# R40 register map
Vendor: Allwinner; Series: R40; File version: 0.1
CPU: CA7 0, little endian, MPU, FPU, double-precision FPU, 0 interrupt priority bits
Registers are 32-bit, read-write, reset 0x0 unless marked. A register's access mark holds for its fields unless they carry their own. Offsets are from the block's base; [hi:lo] are bit positions; {n}, {i} and the like mark numbered series; 'fields as' and 'values as' point back to an identical list.

## TVE0
Base 0x01C94000
Same registers: TVE1 0x01C98000
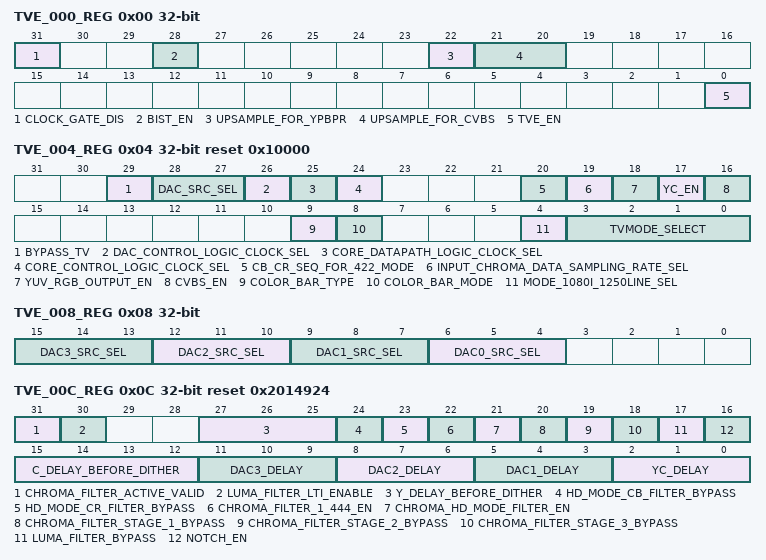
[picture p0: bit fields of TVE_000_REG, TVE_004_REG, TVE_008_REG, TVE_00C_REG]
0x00 TVE_000_REG — TV Encoder Clock Gating Register
  [31] CLOCK_GATE_DIS — CLOCK_GATE_DIS 0: Enable 1: Disable
    0=Enable; 1=Disable
  [28] BIST_EN — BIST_EN 0: Normal mode 1: Bist mode
    0=Normal_mode; 1=Bist_mode
  [22] UPSAMPLE_FOR_YPBPR — upsample for YPbPr 0:1x 1:2x
  [21:20] UPSAMPLE_FOR_CVBS — upsample for CVBS Out up sample 00: 27MHz 01: 54MHz 10: 108MHz 11: 216MHz
    0=_27MHz; 1=_54MHz; 2=_108MHz; 3=_216MHz
  [0] TVE_EN — TVE_EN 0: Disable 1: Enable Note: Video Encoder enable, default disable, write 1 to take it out of the reset state
    0=Disable; 1=Enable Note: Video Encoder enable, default disable, write 1 to take it out of the reset state
0x04 TVE_004_REG reset 0x10000 — TV Encoder Configuration Register
  [29] BYPASS_TV — 0: Disable 1: Enable
    0=Disable; 1=Enable
  [28:27] DAC_SRC_SEL — 00: TV Encoder 01: LCD controller, override all other TV encoder setting, the DAC clock can from LCD controller. 10: DAC test mode,DAC using DAC clock 11: DAC test mode, DAC using AHB clock
  [26] DAC_CONTROL_LOGIC_CLOCK_SEL — 0: Using 27MHz clock or 74.25MHz clock depend on CCU setting 1: Using 54MHz clock or 148.5MHz clock depend on CCU setting
    0=_27MHz (Using 27MHz clock or 74.25MHz clock depend on CCU setting); 1=_54MHz (Using 54MHz clock or 148.5MHz clock depend on CCU setting)
  [25] CORE_DATAPATH_LOGIC_CLOCK_SEL — 0: Using 27MHz clock or 74.25MHz clock depend on CCU setting 1: Using 54MHz clock or 148.5MHz clock depend on CCU setting
    values as DAC_CONTROL_LOGIC_CLOCK_SEL
  [24] CORE_CONTROL_LOGIC_CLOCK_SEL — 0: Using 27MHz clock or 74.25MHz clock depend on CCU setting 1: Using 54MHz clock or 148.5MHz clock depend on CCU setting
    values as DAC_CONTROL_LOGIC_CLOCK_SEL
  [20] CB_CR_SEQ_FOR_422_MODE — 0: Cb first 1: Cr first
    0=Cb (Cb first); 1=Cr (Cr first)
  [19] INPUT_CHROMA_DATA_SAMPLING_RATE_SEL — 0: 4:4:4 1: 4:2:2
    0=_4_colon_4_colon_4 (4:4:4); 1=_4_colon_2_colon_2 (4:2:2)
  [18] YUV_RGB_OUTPUT_EN — 0: CVBS or/and Y/C 1: YUV (or RGB) Note: Only apply to SD interlace mode, when in progressive mode, output YPbPr (RGB) only
    0=CVBS (CVBS or/and Y/C); 1=YUV (YUV (or RGB) Note: Only apply to SD interlace mode, when in progressive mode, output YPbPr (RGB) only)
  [17] YC_EN — 0: Y/C is disable 1: Y/C enable Note: S-port Video enable Selection. This bit selects whether the S-port(Y/C) video output is enabled or disabled.
    0=Y_slash_C (Y/C is disable); 1=Y_slash_C_enable (Y/C enable Note: S-port Video enable Selection. This bit selects whether the S-port(Y/C) video output is enabled or disabled.)
  [16] CVBS_EN — 0: Composite video is disabled, Only Y/C is enable 1: Composite video is enabled., CVBS and Y/C enable Note: Composite Video enable Selection This bit selects whether the composite video output (CVBS) is enabled or disabled.
    0=disabled (Composite video is disabled, Only Y/C is enable); 1=enabled (Composite video is enabled., CVBS and Y/C enable Note: Composite Video enable Selection This bit selects whether the composite video output (CVBS) is enabled or disabled.)
  [9] COLOR_BAR_TYPE — 0: 75/7.5/75/7.5 (NTSC), 100/0/75/0(PAL) 1: 100/7.5/100/7.5(NTSC), 100/0/100/0(PAL)
    0=_75_slash_7_point_5_slash_75_slash_7_point_5 (75/7.5/75/7.5 (NTSC), 100/0/75/0(PAL)); 1=_100_slash_7_point_5_slash_100_slash_7_point_5_openingparen_NTSC_closingparen_ (100/7.5/100/7.5(NTSC), 100/0/100/0(PAL))
  [8] COLOR_BAR_MODE — 0: The Video Encoder input is coming from the Display Engineer 1: The Video Encoder input is coming from an internal standard color bar generator. Note: Standard Color bar input selection This bit selects whether the Video Encoder video data input is replaced by an internal standard color bar generator or not.
    0=coming_from_the_Display (The Video Encoder input is coming from the Display Engineer); 1=coming_from_an (The Video Encoder input is coming from an internal standard color bar generator. Note: Standard Color bar input selection This bit selects whether the Video Encoder video data input is replaced by an internal standard color bar generator or not.)
  [4] MODE_1080I_1250LINE_SEL — 0: 1125 Line mode 1: 1250 Line mode
    0=1125 Line mode; 1=1250 Line mode
  [3:0] TVMODE_SELECT — 0000: 480i 0001: 576i 0010: 480p 0011: 576p 01xx: Reserved 100x: Reserved 101x: 720p 110x: 1080i 111x: 1080p Note: Changing this register value will cause some relative register setting to relative value.
    0=_480i; 1=_576i; 2=_480p; 3=_576p; 10=_720p; 12=_1080i; 14=1080p Note: Changing this register value will cause some relative register setting to relative value
0x08 TVE_008_REG — TV Encoder DAC Register1
  [all] fields
    0=Composite; 1=Luma; 2=Chroma; 4=Y_slash_Green (Y/Green); 5=U_slash_Pb_slash_Blue (U/Pb/Blue); 6=V_slash_Pr_slash_Red (V/Pr/Red)
  [3n+6:3n+4] DAC{n}_SRC_SEL (n=0..3) — 000: Composite 001: Luma 010: Chroma 011: Reserved 100: Y/Green 101: U/Pb/Blue 110: V/Pr/Red 111: Reserved
0x0C TVE_00C_REG reset 0x2014924 — TV Encoder Notch and DAC Delay Register
  [31] CHROMA_FILTER_ACTIVE_VALID — 0: Disable 1: Enable
    0=Disable; 1=Enable
  [30] LUMA_FILTER_LTI_ENABLE — 0: Disable Luma filter lti 1: Enable Luma filter lti
    0=Disable Luma filter lti; 1=Enable Luma filter lti
  [27:25] Y_DELAY_BEFORE_DITHER
  [24] HD_MODE_CB_FILTER_BYPASS — 0: Bypass Enable 1: Bypass Disable
    0=Bypass_Enable; 1=Bypass_Disable
  [23] HD_MODE_CR_FILTER_BYPASS — 0: Bypass Enable 1: Bypass Disable
    0=Bypass_Enable; 1=Bypass_Disable
  [22] CHROMA_FILTER_1_444_EN — 0: Chroma Filter 1 444 Disable 1: Chroma Filter 1 444 Enable
    0=Chroma_Filter_1_444_Disable; 1=Chroma_Filter_1_444_Enable
  [21] CHROMA_HD_MODE_FILTER_EN — 0: Chroma HD Filter Disable 1: Chroma HD Filter Enable
    0=Chroma_HD_Filter_Disable; 1=Chroma_HD_Filter_Enable
  [20] CHROMA_FILTER_STAGE_1_BYPASS — 0: Chroma Filter Stage 1 Enable 1: Chroma Filter Stage 1 bypass
    0=Chroma_Filter_Stage_1_Enable; 1=Chroma_Filter_Stage_1_bypass
  [19] CHROMA_FILTER_STAGE_2_BYPASS — 0: Chroma Filter Stage 2 Enable 1: Chroma Filter Stage 2 bypass
    0=Chroma_Filter_Stage_2_Enable; 1=Chroma_Filter_Stage_2_bypass
  [18] CHROMA_FILTER_STAGE_3_BYPASS — 0: Chroma Filter Stage 3 Enable 1: Chroma Filter Stage 3 bypass
    0=Chroma_Filter_Stage_3_Enable; 1=Chroma_Filter_Stage_3_bypass
  [17] LUMA_FILTER_BYPASS — 0: Luma Filter Enable 1: Luma Filter bypass
    0=Luma_Filter_Enable; 1=Luma_Filter_bypass
  [16] NOTCH_EN — 0: The luma notch filter is bypassed 1: The luma notch filter is operating Luma notch filter on/off selection Note: This bit selects if the luma notch filter is operating or bypassed.
    0=bypassed (The luma notch filter is bypassed); 1=operating (The luma notch filter is operating Luma notch filter on/off selection Note: This bit selects if the luma notch filter is operating or bypassed.)
  [15:12] C_DELAY_BEFORE_DITHER
  [11:9] DAC3_DELAY — 000: The DAC3 lags DAC0 by 4 encoder clock cycles 001: The DAC3 lags DAC0 by 3 encoder clock cycles 010: The DAC3 lags DAC0 by 2 encoder clock cycles 011: The DAC3 lags DAC0 by 1 encoder clock cycle 100: There is no delay between the DAC0 and DAC3 signals 001: The DAC0 lags DAC3 by 1 encoder clock cycle 010: The DAC0 lags DAC3 by 2 encoder clock cycles 011: The DAC0 lags DAC3 by 3 encoder clock cycles DAC3 and DAC0 paths relative delays (default=4 stages) Relative delay between DAC3 and DAC0 selection. These bits select the relative delay between the DAC3 samples and DAC0 samples. The delay range from 4 encoder clock cycles of DAC3 lagging the DAC0 samples to 3 encoder clock cycles of DAC3 preceding the DAC0 samples.
    0=DAC3_lags_DAC0_by_4 (The DAC3 lags DAC0 by 4 encoder clock cycles); 1=DAC3_lags_DAC0_by_3 (The DAC3 lags DAC0 by 3 encoder clock cycles); 2=DAC3_lags_DAC0_by_2 (The DAC3 lags DAC0 by 2 encoder clock cycles); 3=DAC3_lags_DAC0_by_1 (The DAC3 lags DAC0 by 1 encoder clock cycle); 4=no_delay_between_the_DAC0 (There is no delay between the DAC0 and DAC3 signals); 1=DAC0_lags_DAC3_by_1 (The DAC0 lags DAC3 by 1 encoder clock cycle); 2=DAC0_lags_DAC3_by_2 (The DAC0 lags DAC3 by 2 encoder clock cycles); 3=DAC0_lags_DAC3_by_3 (The DAC0 lags DAC3 by 3 encoder clock cycles DAC3 and DAC0 paths relative delays (default=4 stages) Relative delay between DAC3 and DAC0 selection. These bits select the relative delay between the DAC3 samples and DAC0 samples. The delay range from 4 encoder clock cycles of DAC3 lagging the DAC0 samples to 3 encoder clock cycles of DAC3 preceding the DAC0 samples.)
  [8:6] DAC2_DELAY — 000: The DAC2 lags DAC0 by 4 encoder clock cycles 001: The DAC2 lags DAC0 by 3 encoder clock cycles 010: The DAC2 lags DAC0 by 2 encoder clock cycles 011: The DAC2 lags DAC0 by 1 encoder clock cycle 100: There is no delay between the DAC0 and DAC2 signals 001: The DAC0 lags DAC2 by 1 encoder clock cycle 010: The DAC0 lags DAC2 by 2 encoder clock cycles 011: The DAC0 lags DAC2 by D encoder clock cycles DAC2 and DAC0 paths relative delays (default=4 stages) Relative delay between DAC2 and DAC0 selection. These bits select the relative delay between the DAC2 samples and DAC0 samples. The delay range from 4 encoder clock cycles of DAC2 lagging the DAC0 samples to 3 encoder clock cycles of DAC2 preceding the DAC0 samples.
    0=DAC2_lags_DAC0_by_4 (The DAC2 lags DAC0 by 4 encoder clock cycles); 1=DAC2_lags_DAC0_by_3 (The DAC2 lags DAC0 by 3 encoder clock cycles); 2=DAC2_lags_DAC0_by_2 (The DAC2 lags DAC0 by 2 encoder clock cycles); 3=DAC2_lags_DAC0_by_1 (The DAC2 lags DAC0 by 1 encoder clock cycle); 4=no_delay_between_the_DAC0 (There is no delay between the DAC0 and DAC2 signals); 1=DAC0_lags_DAC2_by_1 (The DAC0 lags DAC2 by 1 encoder clock cycle); 2=DAC0_lags_DAC2_by_2 (The DAC0 lags DAC2 by 2 encoder clock cycles); 3=DAC0_lags_DAC2_by_D (The DAC0 lags DAC2 by D encoder clock cycles DAC2 and DAC0 paths relative delays (default=4 stages) Relative delay between DAC2 and DAC0 selection. These bits select the relative delay between the DAC2 samples and DAC0 samples. The delay range from 4 encoder clock cycles of DAC2 lagging the DAC0 samples to 3 encoder clock cycles of DAC2 preceding the DAC0 samples.)
  [5:3] DAC1_DELAY — 000: The DAC1 lags DAC0 by 4 encoder clock cycles 001: The DAC1 lags DAC0 by 3 encoder clock cycles 010: The DAC1 lags DAC0 by 2 encoder clock cycles DAC1 and DAC0 paths relative delays (default=4 stages) Relative delay between DAC1 and DAC0 selection. These bits select the relative delay between the DAC1 samples and DAC0 samples. The delay range from 4 encoder clock cycles of DAC1 lagging the DAC0 samples to 3 encoder clock cycles of DAC1 preceding the DAC0 samples. 011: The DAC1 lags DAC0 by 1 encoder clock cycle 100: There is no delay between the DAC1 and DAC0 signals 001: The DAC0 lags DAC1 by 1 encoder clock cycle 010: The DAC0 lags DAC1 by 2 encoder clock cycles 011: The DAC0 lags DAC1 by D encoder clock cycles
    0=DAC1_lags_DAC0_by_4 (The DAC1 lags DAC0 by 4 encoder clock cycles); 1=DAC1_lags_DAC0_by_3 (The DAC1 lags DAC0 by 3 encoder clock cycles); 2=DAC1_lags_DAC0_by_2 (The DAC1 lags DAC0 by 2 encoder clock cycles DAC1 and DAC0 paths relative delays (default=4 stages) Relative delay between DAC1 and DAC0 selection. These bits select the relative delay between the DAC1 samples and DAC0 samples. The delay range from 4 encoder clock cycles of DAC1 lagging the DAC0 samples to 3 encoder clock cycles of DAC1 preceding the DAC0 samples.); 3=DAC1_lags_DAC0_by_1 (The DAC1 lags DAC0 by 1 encoder clock cycle); 4=no_delay_between_the_DAC1 (There is no delay between the DAC1 and DAC0 signals); 1=DAC0_lags_DAC1_by_1 (The DAC0 lags DAC1 by 1 encoder clock cycle); 2=DAC0_lags_DAC1_by_2 (The DAC0 lags DAC1 by 2 encoder clock cycles); 3=DAC0_lags_DAC1_by_D (The DAC0 lags DAC1 by D encoder clock cycles)
  [2:0] YC_DELAY — luma and chroma paths relative delays (default=4 stages) Relative delay between U/V and Y selection. These bits select the relative delay between the U and V samples and Y samples. The delay range from 4 encoder clock cycles of Y lagging the U and V samples to 3 encoder clock cycles of Y preceding the U and V samples. 000: The Y lags C by 4 encoder clock cycles 001: The Y lags C by 3 encoder clock cycles 010: The Y lags C by 2 encoder clock cycles 011: The Y lags C by 1 encoder clock cycle 100: There is no delay between the Y and C signals 101: The C lags Y by 1 encoder clock cycle 110: The C lags Y by 2 encoder clock cycles 111: The C lags Y by 3 encoder clock cycles
    0=Y_lags_C_by_4 (The Y lags C by 4 encoder clock cycles); 1=Y_lags_C_by_3 (The Y lags C by 3 encoder clock cycles); 2=Y_lags_C_by_2 (The Y lags C by 2 encoder clock cycles); 3=Y_lags_C_by_1 (The Y lags C by 1 encoder clock cycle); 4=no_delay_between_the_Y (There is no delay between the Y and C signals); 5=C_lags_Y_by_1 (The C lags Y by 1 encoder clock cycle); 6=C_lags_Y_by_2 (The C lags Y by 2 encoder clock cycles); 7=C_lags_Y_by_3 (The C lags Y by 3 encoder clock cycles)
0x10 TVE_010_REG reset 0x21F07C1F — TV Encoder chroma frequency Register
  [31:0] CHROMA_FREQ — Specify the ratio between the color burst frequency. 32 bits unsigned fraction. Default value is h21f07c1f, which is compatible with NTSC specs. 3.5795455 MHz (X`21F07C1F`): NTSC-M, NTSC-J 4.43361875 MHz(X`2A098ACB`): PAL-B, D, G, H,I, N 3.582056 MHz (X`21F69446`): PAL-N(Argentina) 3.579611 MHz (X`21E6EFE3`): PAL-M
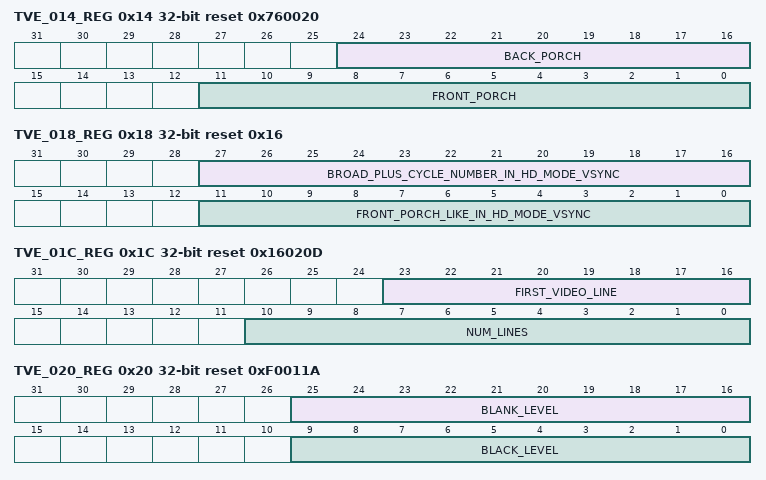
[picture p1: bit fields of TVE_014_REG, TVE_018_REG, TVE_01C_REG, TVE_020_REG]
0x14 TVE_014_REG reset 0x760020 — TV Encoder Front/Back Porch Register
  [24:16] BACK_PORCH — Specify the width of the back porch in encoder clock cycles. Min value is ( +17 . 8 bits unsigned integer. Default value is 118. 720p mode, is 260 1080i/p mode, is 192
  [11:0] FRONT_PORCH — Must be even. Specify the width of the front porch in encoder clock cycles. 6 bits unsigned even integer. Allowed range is 10 to 62. Default value is 32 in 1080i mode is 44.
0x18 TVE_018_REG reset 0x16 — TV Encoder HD mode VSYNC Register
  [27:16] BROAD_PLUS_CYCLE_NUMBER_IN_HD_MODE_VSYNC, [11:0] FRONT_PORCH_LIKE_IN_HD_MODE_VSYNC
0x1C TVE_01C_REG reset 0x16020D — TV Encoder Line Number Register
  [23:16] FIRST_VIDEO_LINE — Specify the index of the first line in a field/frame to have active video. 8 bits unsigned integer. For interlaced video: When VSync5=B`0`, FirstVideoLine is restricted to be greater than 7. When VSync5=B`1`, FirstVideoLine is restricted to be greater than 9. Default value is 21.
  [10:0] NUM_LINES — Specify the total number of lines in a video frame. 11 bits unsigned integer. Allowed range is 0 to 2048. Default value is 525. For interlaced video: When NTSC, and FirstVideoLine is greater than 20, then NumLines is restricted to be greater than 2*(FirstVideoLine+18). When NTSC, and FirstVideoLine is not greater than 20, then NumLines is restricted to be greater than 77. When PAL, and FirstVideoLine is greater than 22, then NumLines is restricted to be greater than 2*(FirstVideoLine+18). When PAL, and FirstVideoLine is not greater than 22, then NumLines is restricted to be greater than 81. If NumLines is even, then it is restricted to be divisible by 4. If NumLines is odd, then it is restricted to be divisible by 4 with a remainder of 1.
0x20 TVE_020_REG reset 0xF0011A — TV Encoder Level Register
  [25:16] BLANK_LEVEL — Specify the blank level setting for active lines. 10 bits unsigned integer. Allowed range 0 to 1023. Default value is 0xF0(dec240).
  [9:0] BLACK_LEVEL — Specify the black level setting. 10 bits unsigned integer. Allowed range is 240 to 1023. Default value is 282.
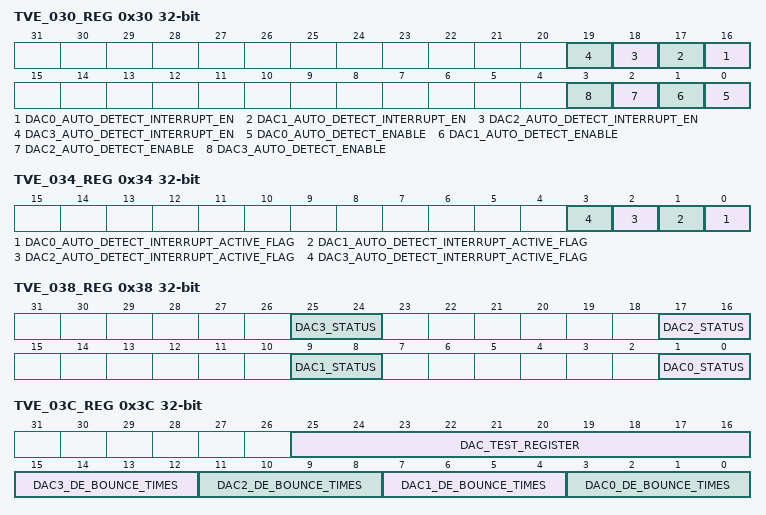
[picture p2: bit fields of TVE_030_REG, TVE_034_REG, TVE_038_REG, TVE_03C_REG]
0x30 TVE_030_REG — TV Encoder Auto Detection Enable Register
  [n+16] DAC{n}_AUTO_DETECT_INTERRUPT_EN (n=0..3), [n] DAC{n}_AUTO_DETECT_ENABLE (n=0..3)
0x34 TVE_034_REG — TV Encoder Auto Detection Interrupt Status Register
  [n] DAC{n}_AUTO_DETECT_INTERRUPT_ACTIVE_FLAG (n=0..3) — Write 1 to inactive DAC{n} auto detection interrupt
0x38 TVE_038_REG — TV Encoder Auto Detection Status Register
  [all] fields
    0=Unconnected; 1=Connected; 3=Short to ground
  [8n+1:8n] DAC{n}_STATUS (n=0..3) — 00: Unconnected 01: Connected 11: Short to ground 10: Reserved
0x3C TVE_03C_REG — TV Encoder Auto Detection de-bounce Setting Register
  [25:16] DAC_TEST_REGISTER, [4n+3:4n] DAC{n}_DE_BOUNCE_TIMES (n=0..3)
0xF8 TVE_0F8_REG — TV Encoder Auto Detect Configuration Register0
  [9:0] DETECT_PULSE_VALUE — Use for DAC data input at auto detect pluse
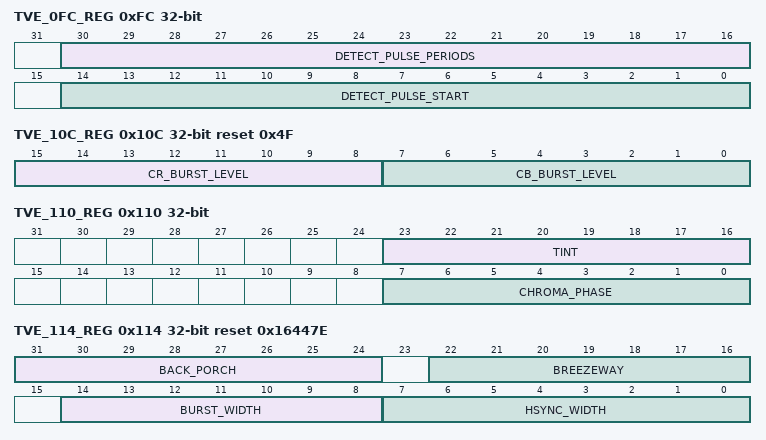
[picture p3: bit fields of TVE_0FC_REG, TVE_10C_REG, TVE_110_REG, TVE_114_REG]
0xFC TVE_0FC_REG — TV Encoder Auto Detect Configuration Register1
  [30:16] DETECT_PULSE_PERIODS — Use 32K clock
  [14:0] DETECT_PULSE_START
0x100 TVE_100_REG reset 0x1 — TV Encoder Color Burst Phase Reset Configuration Register
  [1:0] COLOR_PHASE_RESET — Color burst phase period selection These bits select the number of fields or lines after which the color burst phase is reset to its initial value as specified by the ChromaPhase parameter, This parameter is application only for interlaced video. 00: 8 field 01: 4 field 10: 2 lines 11: only once
    0=_8; 1=_4; 2=2 lines; 3=only_once
0x104 TVE_104_REG — TV Encoder VSYNC Number Register
  [0] VSYNC5 — VSync5 Number of equalization pulse selection This bit selects whether the number of equalization pulses is 5 or 6. This parameter is applicable only for interlaced video. 0: 5 equalization pulse(default) 1: 6 equalization pulses
    0=5 equalization pulse(default); 1=6 equalization pulses
0x108 TVE_108_REG reset 0x2 — TV Encoder Notch Filter Frequency Register
  [2:0] NOTCH_FREQ — Luma notch filter center frequency selection These bits select the luma notch filter (which is a band-reject filter) center frequency. In two of the selections, the filter width affects also the selection of the center frequency. 000: 1.1875 001: 1.1406 010: 1.0938 when notch_wide value is B`1` (this selection is proper for CCIR-NTSC), or 1.0000 when notch_wide value is B`0` 011: 0.9922. This selection is proper for NTSC with square pixels 100: 0.9531. This selection is proper for PAL with square pixel 101: 0.8359 when notch_wide value is B`1` (this selection is proper for CCIR-PAL), or 0.7734 when notch_wide value is B`0` 110: 0.7813 111: 0.7188
    0=_1_point_1875 (1.1875); 1=_1_point_1406 (1.1406); 2=_1_point_0938 (1.0938 when notch_wide value is B`1` (this selection is proper for CCIR-NTSC), or 1.0000 when notch_wide value is B`0`); 3=_0_point_9922 (0.9922. This selection is proper for NTSC with square pixels); 4=_0_point_9531 (0.9531. This selection is proper for PAL with square pixel); 5=_0_point_8359 (0.8359 when notch_wide value is B`1` (this selection is proper for CCIR-PAL), or 0.7734 when notch_wide value is B`0`); 6=_0_point_7813 (0.7813); 7=_0_point_7188 (0.7188)
0x10C TVE_10C_REG reset 0x4F — TV Encoder Cb/Cr Level/Gain Register
  [15:8] CR_BURST_LEVEL — Specify the amplitude of the Cr burst. 8 bit 2`s complement integer. Allowed range is (-127) to 127. Default value is 0.
  [7:0] CB_BURST_LEVEL — Specify the amplitude of the Cb burst. 8 bit 2`s complement integer. Allowed range is (-127) to 127. Default value is 60.
0x110 TVE_110_REG — TV Encoder Tint and Color Burst Phase Register
  [23:16] TINT — Specify the tint adjustment of the chroma signal for CVBS and Y/C outputs. The adjustment is effected by setting the sub-carrier phase to the value of this parameter. 8.8 bit unsigned fraction. Units are cycles of the color burst frequency. Default value is 0.
  [7:0] CHROMA_PHASE — Specify the color burst initial phase ( . 8 bit unsigned fraction. Units are cycles of the color burst frequency. Default value is X`00`. The color burst is set to this phase at the first and then reset to the same value at further s as specified by the bits of the parameter (see above)
0x114 TVE_114_REG reset 0x16447E — TV Encoder Burst Width Register
  [31:24] BACK_PORCH — Breezeway like in HD mode VSync 720p mode, is 220 2080i/p mode is 88(default)
  [22:16] BREEZEWAY — Must be even. Specify the width of the breezeway in encoder clock cycles. 5 bit unsigned integer. Allowed range is 0 to 31. Default value is 22 In 1080i mode, is 44 In 1080p mode, is 44 In 720p mode,is 40
  [14:8] BURST_WIDTH — Specify the width of the color frequency burst in encoder clock cycles. 7 bit unsigned integer. Allowed range is 0 to 127. Default value is 68. In hd mode, ignored
  [7:0] HSYNC_WIDTH — Specify the width of the horizontal sync pulse in encoder clock cycles. Min value is 16. Max value is ( ). Default value is 126. The sum of and is restricted to be divisible by 4. In 720p mode, is 40 In 1080i/p mode, is 44
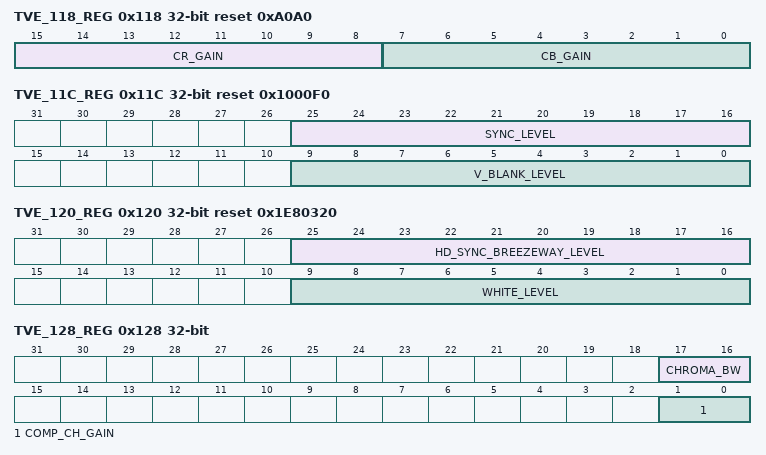
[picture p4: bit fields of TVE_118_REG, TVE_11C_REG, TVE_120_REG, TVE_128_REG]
0x118 TVE_118_REG reset 0xA0A0 — TV Encoder Cb/Cr Gain Register
  [15:8] CR_GAIN — Specify the Cr color gain. 8 bit unsigned fraction. Default value is 139.
  [7:0] CB_GAIN — Specify the Cb color gain. 8 bit unsigned fraction. Default value is 139.
0x11C TVE_11C_REG reset 0x1000F0 — TV Encoder Sync and VBI Level Register
  [25:16] SYNC_LEVEL — Specify the sync pulse level setting. 8 bit unsigned integer. Allowed range is 0 to -1 or -1 (whichever is smaller).
  [9:0] V_BLANK_LEVEL — VBlank_Level Specify the blank level setting for non active lines. 10 bit unsigned integer. Allow range 0 to 1023.
0x120 TVE_120_REG reset 0x1E80320 — TV Encoder White Level Register
  [25:16] HD_SYNC_BREEZEWAY_LEVEL — Specify the breezeway level setting. 10 bit unsigned integer. Allowed range is 0 to 1023. Default value is 488.
  [9:0] WHITE_LEVEL — Specify the white level setting. 10 bit unsigned integer. Allowed range is black_level+1 or vbi_blank_level +1 (whichever is greater) to 1023. Default value is 800.
0x124 TVE_124_REG reset 0x5A0 — TV Encoder Video Active Line Register
  [11:0] ACTIVE_LINE — Specify the width of the video line in encoder clock cycles. 12 bit unsigned multiple of 4 integer. Allowed range is 0 to 4092 Default value is 1440.
0x128 TVE_128_REG — TV Encoder Video Chroma BW and CompGain Register
  [17:16] CHROMA_BW — Chroma filter bandwidth selection This bit specifies whether the bandwidth of the chroma filter is: 00: Narrow width, 0.6MHz 01: Wide width 1.2MHz. 10: Extra width 1.8MHz 11: Ultra width 2.5MHz Default is 0.6MHz(value 0)
    0=Narrow width, 0.6MHz; 1=Wide width 1.2MHz; 2=Extra width 1.8MHz; 3=Ultra width 2.5MHz Default is 0.6MHz(value 0)
  [1:0] COMP_CH_GAIN — Chroma gain selection for the composite video signal. These bits specify the gain of the chroma signal for composing with the luma signal to generate the composite video signal: 00: 100% (B`00`), 01: 25% 10: 50% 11: 75%
    0=_100_percent_ (100% (B`00`),); 1=_25_percent_; 2=_50_percent_; 3=_75_percent_
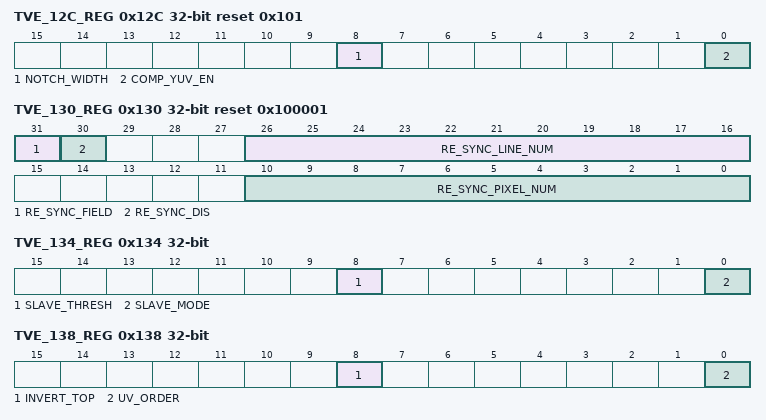
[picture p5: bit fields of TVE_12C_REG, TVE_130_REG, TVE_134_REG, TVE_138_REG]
0x12C TVE_12C_REG reset 0x101 — TV Encoder Register
  [8] NOTCH_WIDTH — Luma notch filter width selection This bit selects the luma notch filter (which is a band-reject filter) width. 0: Narrow 1: Wide
    0=Narrow; 1=Wide
  [0] COMP_YUV_EN — This bit selects if the components video output are the RGB components or the YUV components. 0: The three component outputs are the RGB components. 1: The three component outputs are the YUV components, (i.e. the color conversion unit is by-passed)
    0=three_component_outputs_are_the_RGB (The three component outputs are the RGB components.); 1=three_component_outputs_are_the_YUV (The three component outputs are the YUV components, (i.e. the color conversion unit is by-passed))
0x130 TVE_130_REG reset 0x100001 — TV Encoder Re-sync parameters Register
  [31] RE_SYNC_FIELD
  [30] RE_SYNC_DIS — 0: Re-Sync Enable 1: Re-Sync Disable
    0=re_Sync_Enable; 1=re_Sync_Disable
  [26:16] RE_SYNC_LINE_NUM
  [10:0] RE_SYNC_PIXEL_NUM
0x134 TVE_134_REG — TV Encoder Slave Parameter Register
  [8] SLAVE_THRESH — Horizontal line adjustment threshold selection This bit selects whether the number of lines after which the Video Encoder starts the horizontal line length adjustment is slave mode is 0 or 30. 0: Number of lines is 0 1: Number of lines is 30
    0=Number of lines is 0; 1=Number of lines is 30
  [0] SLAVE_MODE — Slave mode selection This bit selects whether the Video Encoder is sync slave, partial slave or sync master. It should be set to B`0`. 0: The Video Encoder is not a full sync slave (i.e. it is a partial sync slave or a sync master) 1: Reserved
    0=Video (The Video Encoder is not a full sync slave (i.e. it is a partial sync slave or a sync master))
0x138 TVE_138_REG — TV Encoder Configuration Register0
  [8] INVERT_TOP — Field parity input signal (top_field) polarity selection. This bit selects whether the top field is indicated by a high level of the field parity signal or by the low level. The bit is applicable both when the Video Encoder is the sync master and when the Video Encoder is the sync slave. 0: Top field is indicated by low level 1: Top field is indicated by high level
    0=indicated_by_low_level (Top field is indicated by low level); 1=indicated_by_high_level (Top field is indicated by high level)
  [0] UV_ORDER — This bit selects if the sample order at the chroma input to the Video Encoder is Cb first (i.e. Cb 0 Cr 0 Cb 1 Cr 1) or Cr first (i.e. Cr 0 Cb 0 Cr 1 Cb 1). 0: The chroma sample input order is Cb first 1: The chroma sample input order is Cr first
    0=Cb (The chroma sample input order is Cb first); 1=Cr (The chroma sample input order is Cr first)
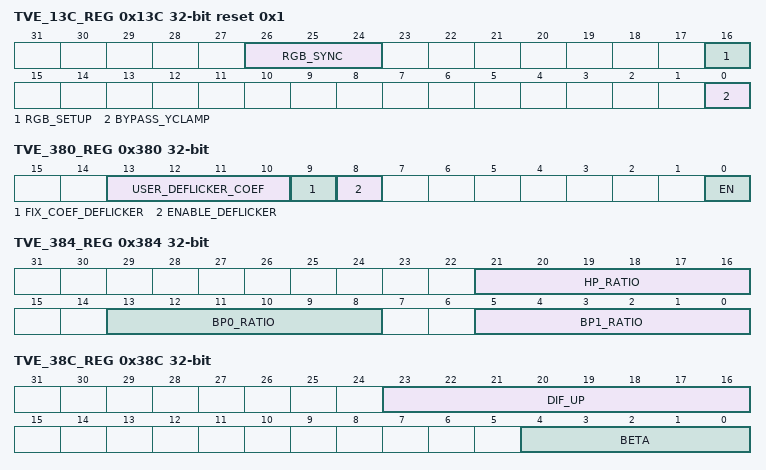
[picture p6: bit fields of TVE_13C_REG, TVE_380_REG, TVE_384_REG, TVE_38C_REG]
0x13C TVE_13C_REG reset 0x1 — TV Encoder Configuration Register1
  [26:24] RGB_SYNC — R, G and B signals sync embedding selection. These bits specify whether the sync signal is added to each of the R, G and B components (B`1`) or not (B`0`). Bit *26+ specify if the R signal have embedded syncs, bit [25] specify if the G signal have embedded syncs and bit [24] specify if the B signal have embedded syncs. When comp_yuv is equal to B`1`, these bits are N.A. and should be set to B`000`. When the value is different from B`000`, should be set to B`1`.
  [16] RGB_SETUP — `Set-up` enable for RGB outputs. This bit specifies if the `set-up` implied value (black_level - blank_level) specified for the CVBS signal is used also for the RGB signals. 0: The `set-up` is not used, or N.A. i.e. comp_yuv is equal to B`1`. 1: The implied `set-up` is used for the RGB signals
    0=`set_minus_up` (The `set-up` is not used, or N.A. i.e. comp_yuv is equal to B`1`.); 1=implied (The implied `set-up` is used for the RGB signals)
  [0] BYPASS_YCLAMP — Y input clamping selection This bit selects whether the Video Encoder Y input is clamped to 64 to 940 or not. When not clamped the expected range is 0 to 1023. The U and V inputs are always clamped to the range 64 to 960. 0: The Video Encoder Y input is clamped 1: The Video Encoder Y input is not clamped
    0=clamped (The Video Encoder Y input is clamped); 1=not_clamped (The Video Encoder Y input is not clamped)
0x380 TVE_380_REG — TV Encoder Low Pass Control Register
  [13:10] USER_DEFLICKER_COEF — up : coef/32 Center :1-coef/16 Down :coef/32
  [9] FIX_COEF_DEFLICKER — 0: Auto deflicker 1: User deflicker
    0=Auto deflicker; 1=User deflicker
  [8] ENABLE_DEFLICKER — 0: Disable deflicker 1: Enable deflicker
    0=Disable deflicker; 1=Enable deflicker
  [0] EN — LP function enable 0: Disable 1: Enable
    0=Disable; 1=Enable
0x384 TVE_384_REG — TV Encoder Low Pass Filter Control Register
  [21:16] HP_RATIO — Default high-pass filter ratio Note: in two's complement. Range from -31 to 31.
  [13:8] BP0_RATIO — Default band-pass filter0 ratio Note: in two's complement. Range from -31 to 31.
  [5:0] BP1_RATIO — Default band-pass filter1 ratio Note: in two's complement. Range from -31 to 31.
0x388 TVE_388_REG — TV Encoder Low Pass Gain Register
  [7:0] GAIN — Peaking gain setting.
0x38C TVE_38C_REG — TV Encoder Low Pass Gain Control Register
  [23:16] DIF_UP — Gain control: limitation threshold.
  [4:0] BETA — Gain control: large gain limitation.
0x390 TVE_390_REG — TV Encoder Low Pass Shoot Control Register
  [5:0] NEG_GAIN — Undershoot gain control.
0x394 TVE_394_REG — TV Encoder Low Pass Coring Register
  [7:0] CORTHR — Coring threshold.
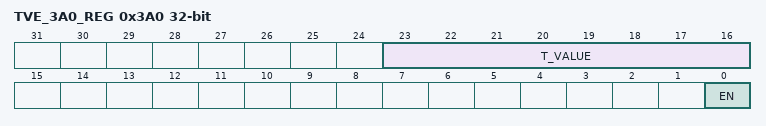
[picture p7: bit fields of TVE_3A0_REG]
0x3A0 TVE_3A0_REG — TV Encoder Noise Reduction Register
  [23:16] T_VALUE, [0] EN
